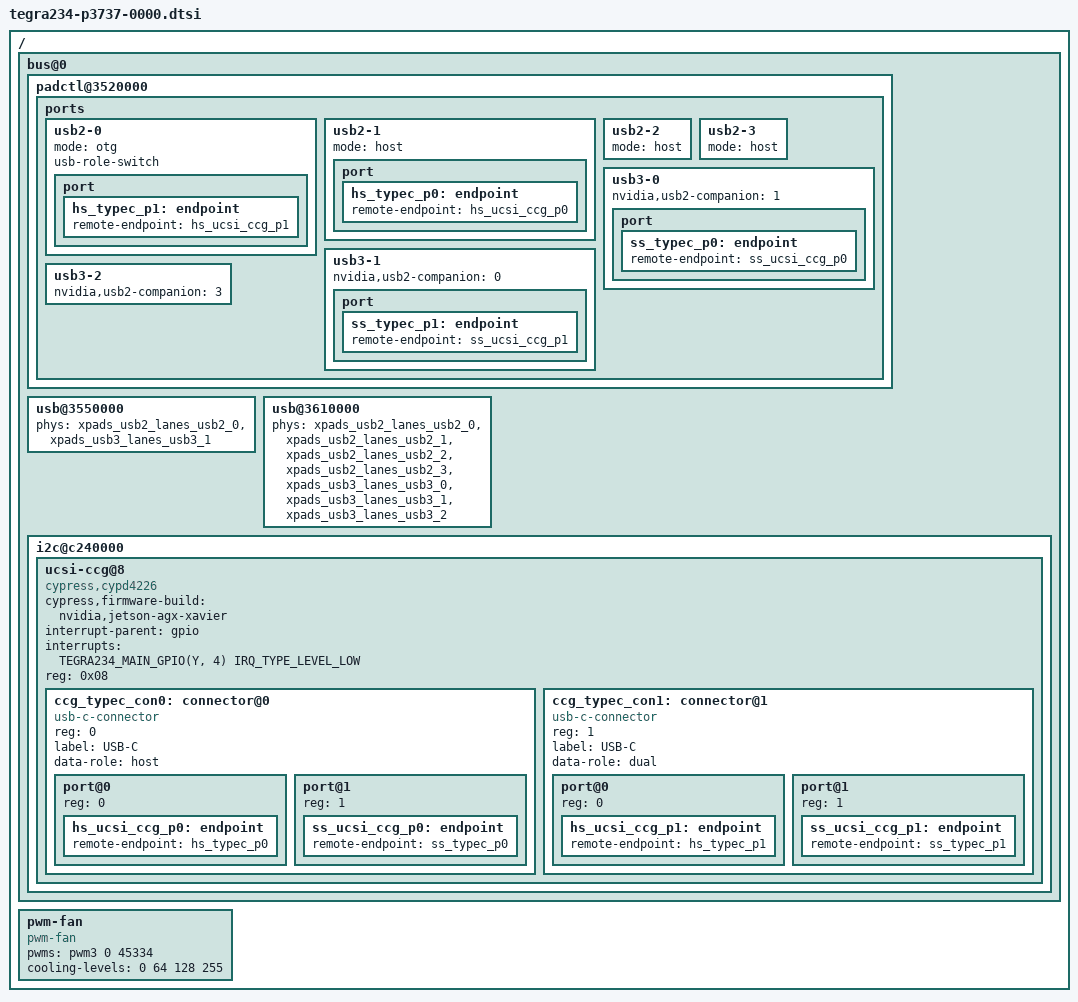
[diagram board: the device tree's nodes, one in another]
// SPDX-License-Identifier: GPL-2.0
// Copyright (c) 2022, NVIDIA CORPORATION & AFFILIATES.  All rights reserved.


/ {
	fragment-t234-p3737-0000@0 {
		target-path = "/";
		__overlay__ {
			bus@0 {
				padctl@3520000 {
					ports {
						usb2-0 {
							mode = "otg";
							usb-role-switch;
							port {
								hs_typec_p1: endpoint {
									remote-endpoint = <&hs_ucsi_ccg_p1>;
								};
							};
						};

						usb2-1 {
							mode = "host";
							port {
								hs_typec_p0: endpoint {
									remote-endpoint = <&hs_ucsi_ccg_p0>;
								};
							};
						};

						usb2-2 {
							mode = "host";
						};

						usb2-3 {
							mode = "host";
						};

						usb3-0 {
							nvidia,usb2-companion = <1>;
							port {
								ss_typec_p0: endpoint {
									remote-endpoint = <&ss_ucsi_ccg_p0>;
								};
							};
						};

						usb3-1 {
							nvidia,usb2-companion = <0>;
							port {
								ss_typec_p1: endpoint {
									remote-endpoint = <&ss_ucsi_ccg_p1>;
								};
							};
						};

						usb3-2 {
							nvidia,usb2-companion = <3>;
						};
					};
				};

				usb@3550000 {
					phys = <&xpads_usb2_lanes_usb2_0>,
						<&xpads_usb3_lanes_usb3_1>;
					phy-names = "usb2-0", "usb3-1";
				};

				usb@3610000 {
					phys =	<&xpads_usb2_lanes_usb2_0>,
						<&xpads_usb2_lanes_usb2_1>,
						<&xpads_usb2_lanes_usb2_2>,
						<&xpads_usb2_lanes_usb2_3>,
						<&xpads_usb3_lanes_usb3_0>,
						<&xpads_usb3_lanes_usb3_1>,
						<&xpads_usb3_lanes_usb3_2>;
					phy-names = "usb2-0", "usb2-1", "usb2-2", "usb2-3",
						"usb3-0", "usb3-1", "usb3-2";
				};

				i2c@c240000 {
					ucsi-ccg@8 {
						compatible = "cypress,cypd4226";
						cypress,firmware-build = "nvidia,jetson-agx-xavier";
						interrupt-parent = <&gpio>;
						interrupts = <TEGRA234_MAIN_GPIO(Y, 4) IRQ_TYPE_LEVEL_LOW>;
						reg = <0x08>;
						#address-cells = <1>;
						#size-cells = <0>;
						ccg_typec_con0: connector@0 {
							compatible = "usb-c-connector";
							reg = <0>;
							label = "USB-C";
							data-role = "host";
							#address-cells = <1>;
							#size-cells = <0>;
							port@0 {
								reg = <0>;
								hs_ucsi_ccg_p0: endpoint {
									remote-endpoint = <&hs_typec_p0>;
								};
							};
							port@1 {
								reg = <1>;
								ss_ucsi_ccg_p0: endpoint {
									remote-endpoint = <&ss_typec_p0>;
								};
							};
						};
						ccg_typec_con1: connector@1 {
							compatible = "usb-c-connector";
							reg = <1>;
							label = "USB-C";
							data-role = "dual";
							#address-cells = <1>;
							#size-cells = <0>;
							port@0 {
								reg = <0>;
								hs_ucsi_ccg_p1: endpoint {
									remote-endpoint = <&hs_typec_p1>;
								};
							};
							port@1 {
								reg = <1>;
								ss_ucsi_ccg_p1: endpoint {
									remote-endpoint = <&ss_typec_p1>;
								};
							};
						};
					};
				};
			};

			pwm-fan {
				compatible = "pwm-fan";
				pwms = <&pwm3 0 45334>;
				cooling-levels = <0 64 128 255>;
				#cooling-cells = <2>;
			};
		};
	};
};
